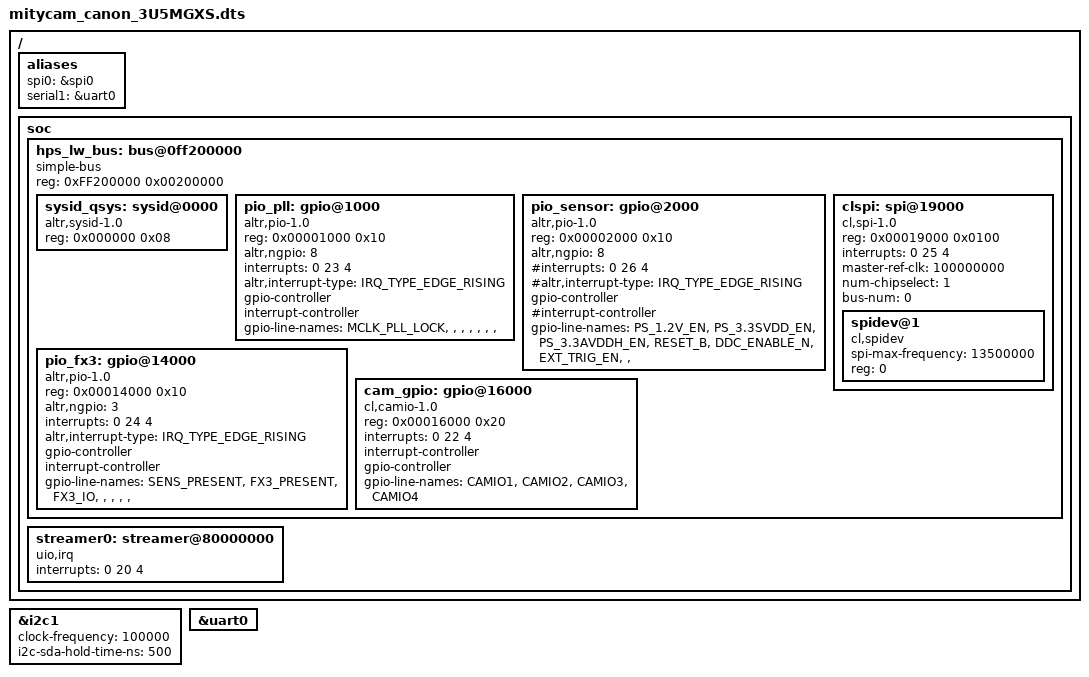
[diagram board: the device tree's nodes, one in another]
/*
 * Copyright (C) 2014-2015 Altera Corporation <www.altera.com>
 *
 * This program is free software; you can redistribute it and/or modify
 * it under the terms of the GNU General Public License as published by
 * the Free Software Foundation; either version 2 of the License, or
 * (at your option) any later version.
 *
 * This program is distributed in the hope that it will be useful,
 * but WITHOUT ANY WARRANTY; without even the implied warranty of
 * MERCHANTABILITY or FITNESS FOR A PARTICULAR PURPOSE.  See the
 * GNU General Public License for more details.
 *
 * You should have received a copy of the GNU General Public License
 * along with this program.  If not, see <http://www.gnu.org/licenses/>.
 */

/dts-v1/;
#include "mitysom_a10s_dsc.dtsi"

/ {
	aliases {
		spi0 = &spi0;
		serial1 = &uart0;
	};

	soc {
		hps_lw_bus: bus@0ff200000 {
			compatible = "simple-bus";
			reg = <0xFF200000 0x00200000>;
			#address-cells = <1>;
			#size-cells = <1>;
			ranges = <0x0 0xFF200000 0x00200000>;
			status = "okay";

			sysid_qsys: sysid@0000 {
				compatible = "altr,sysid-1.0";
				reg = <0x000000 0x08>;
			};

			/* (51-32)=19 is zero */
			pio_pll: gpio@1000 {
				compatible = "altr,pio-1.0";
				reg = <0x00001000 0x10>;
				altr,ngpio = <8>;
				interrupts = <0 23 4>;
				altr,interrupt-type = <IRQ_TYPE_EDGE_RISING>;
				#gpio-cells = <2>;
				gpio-controller;
				#interrupt-cells = <1>;
				interrupt-controller;
				gpio-line-names = "MCLK_PLL_LOCK", "", "", "", "", "", "", "";
			};

			pio_sensor: gpio@2000 {
				compatible = "altr,pio-1.0";
				reg = <0x00002000 0x10>;
				altr,ngpio = <8>;
				#interrupts = <0 26 4>;
				#altr,interrupt-type = <IRQ_TYPE_EDGE_RISING>;
				#gpio-cells = <2>;
				gpio-controller;
				#interrupt-cells = <1>;
				#interrupt-controller;
				gpio-line-names = "PS_1.2V_EN", "PS_3.3SVDD_EN", "PS_3.3AVDDH_EN", "RESET_B", "DDC_ENABLE_N", "EXT_TRIG_EN", "", "";
			};

			/* pll_reconfig  @04000, managed in userspace */
			/* canon_3u5mgxs @10000, managed in userspace */
			/* pwm           @11000, managed in userspace */
			/* sgdma_desc    @12000, managed in userspace */
			/* sgdma_ctrl    @13000, managed in userspace */

			pio_fx3: gpio@14000 {
				compatible = "altr,pio-1.0";
				reg = <0x00014000 0x10>;
				altr,ngpio = <3>;
				interrupts = <0 24 4>;
				altr,interrupt-type = <IRQ_TYPE_EDGE_RISING>;
				#gpio-cells = <2>;
				gpio-controller;
				#interrupt-cells = <1>;
				interrupt-controller;
				gpio-line-names = "SENS_PRESENT", "FX3_PRESENT", "FX3_IO", "", "", "", "", "";
			};

			/* bad_pix    @15000, managed in userspace */

			cam_gpio: gpio@16000 {
				compatible = "cl,camio-1.0";
				reg = <0x00016000 0x20>;
				interrupts = <0 22 4>;
				/* virtual_irq_start = <342>; */
				interrupt-controller;
				#interrupt-cells = <2>;
				gpio-controller;
				#gpio-cells=<2>;
				gpio-line-names = "CAMIO1", "CAMIO2", "CAMIO3", "CAMIO4";
			};

			/* pixel_shift @17000, managed in userspace */
			/* stream_to_sdram @18000, managed in userspace */

			clspi: spi@19000 {
				compatible = "cl,spi-1.0";
				#address-cells = <1>;
				#size-cells = <0>;
				reg = <0x00019000 0x0100>;
				interrupts = <0 25 4>;
				master-ref-clk = <100000000>;
				num-chipselect = <1>;
				bus-num = <0>;

				spidev@1 {
					compatible = "cl,spidev";
					/* Sensor supports up to 13.5Mhz */
					spi-max-frequency = <13500000>;
					reg = <0>;
				};
			};

			/* u3v_sgdma       @20000, managed in userspace */
			/* u3v_sgdma_desc  @21000, managed in userspace */
			/* u3v_fx3         @22000, managed in userspace */
		};

		streamer0: streamer@80000000 {
			compatible = "uio,irq";
			interrupts = <0 20 4>;
		};
	};
};

&i2c1 {
	status = "okay";
	clock-frequency = <100000>;
        i2c-sda-hold-time-ns = <500>;


	/* USB IO Tri-Color LED */
	/* disabled - used directly by ARM software */
	/* 
	led@62 {
		compatible = "nxp,pca9553";
		reg = <0x62>;
	}; */

	/* Sensor board */

};

/* FX3 comms interface */
&uart0 {
	status = "okay";
};

